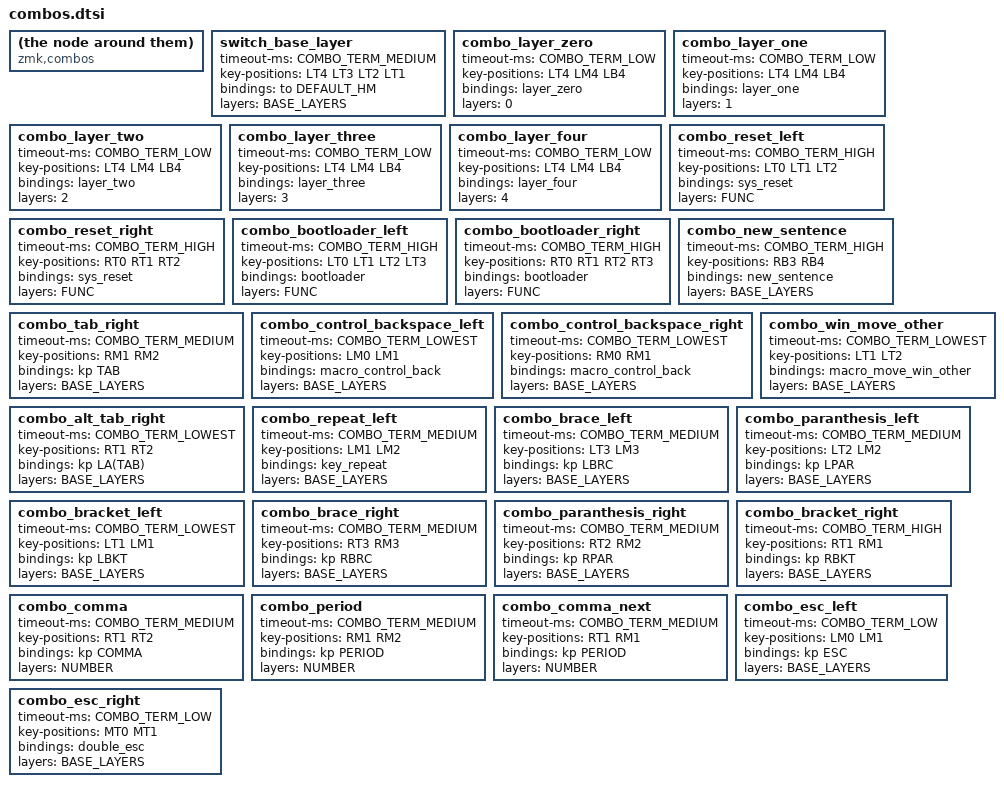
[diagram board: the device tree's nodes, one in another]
compatible = "zmk,combos";
#include "../zmk-nodefree-config/keypos_def/keypos_34keys.h"
#define KEYS_L LT0 LT1 LT2 LT3 LT4 LM0 LM1 LM2 LM3 LM4 LB0 LB1 LB2 LB3 LB4  // left-hand keys
#define KEYS_R RT0 RT1 RT2 RT3 RT4 RM0 RM1 RM2 RM3 RM4 RB0 RB1 RB2 RB3 RB4  // right-hand keys
#define THUMBS LH1 LH0 RH0 RH1  // tHumb keys

#define COMBO_TERM_LOWEST 15
#define COMBO_TERM_LOW 30
#define COMBO_TERM_MEDIUM 40
#define COMBO_TERM_HIGH 50

#define BASE_LAYERS DEFAULT_HM DEFAULT_HM_ONE DEFAULT_HM_TWO DEFAULT_HM_THREE DEFAULT_HM_NONE
// #undef COMBO_HOOK
// #define COMBO_HOOK global-quick-tap-ms = <100>;

/* 5 columns 
0	1	2	3	4		5	6	7	8	9
10	11	12	13	14		15	16	17	18	19
20	21	22	23	24		25	26	27	28	29
		30	31				32	33		
*/

/*                KEY POSITIONS

  ╭─────────────────────╮ ╭─────────────────────╮
  │ LT4 LT3 LT2 LT1 LT0 │ │ RT0 RT1 RT2 RT3 RT4 │
  │ LM4 LM3 LM2 LM1 LM0 │ │ RM0 RM1 RM2 RM3 RM4 │
  │ LB4 LB3 LB2 LB1 LB0 │ │ RB0 RB1 RB2 RB3 RB4 │
  ╰───────╮ LH2 LH1 LH0 │ │ RH0 RH1 RH2 ╭───────╯
          ╰─────────────╯ ╰─────────────╯ */


// layers
// What layer am I on?
// Device settings
// Tricks
// modifiers
// symbols
// keys

// layers

switch_base_layer {
    timeout-ms = <COMBO_TERM_MEDIUM>;
    key-positions = <LT4 LT3 LT2 LT1>;
    bindings = <&to DEFAULT_HM>;
    layers = <BASE_LAYERS>;
};


// What layer am I on?
combo_layer_zero {
    timeout-ms = <COMBO_TERM_LOW>;
    key-positions = <LT4 LM4 LB4>;
    bindings = <&layer_zero>;
    layers = <0>;
};

combo_layer_one {
    timeout-ms = <COMBO_TERM_LOW>;
    key-positions = <LT4 LM4 LB4>;
    bindings = <&layer_one>;
    layers = <1>;
};

combo_layer_two {
    timeout-ms = <COMBO_TERM_LOW>;
    key-positions = <LT4 LM4 LB4>;
    bindings = <&layer_two>;
    layers = <2>;
};

combo_layer_three {
    timeout-ms = <COMBO_TERM_LOW>;
    key-positions = <LT4 LM4 LB4>;
    bindings = <&layer_three>;
    layers = <3>;
};

combo_layer_four {
    timeout-ms = <COMBO_TERM_LOW>;
    key-positions = <LT4 LM4 LB4>;
    bindings = <&layer_four>;
    layers = <4>;
};

// Device settings

combo_reset_left {
    timeout-ms = <COMBO_TERM_HIGH>;
    key-positions = <LT0 LT1 LT2>;
    bindings = <&sys_reset>;
    layers = <FUNC>;
};
    
combo_reset_right {
    timeout-ms = <COMBO_TERM_HIGH>; 
    key-positions = <RT0 RT1 RT2>;
    bindings = <&sys_reset>;
    layers = <FUNC>;
};
    
combo_bootloader_left {
    timeout-ms = <COMBO_TERM_HIGH>;
    key-positions = <LT0 LT1 LT2 LT3>;
    bindings = <&bootloader>;
    layers = <FUNC>;
};

combo_bootloader_right {
    timeout-ms = <COMBO_TERM_HIGH>;
    key-positions = <RT0 RT1 RT2 RT3>;
    bindings = <&bootloader>;
    layers = <FUNC>;
};


// Tricks 

combo_new_sentence {
    timeout-ms = <COMBO_TERM_HIGH>;
    key-positions = <RB3 RB4>;
    bindings = <&new_sentence>;
    layers = <BASE_LAYERS>;
};


// modifiers

combo_tab_right {
    timeout-ms = <COMBO_TERM_MEDIUM>;
    key-positions = <RM1 RM2>;
    bindings = <&kp TAB>;
    layers = <BASE_LAYERS>;
};

combo_control_backspace_left {
    timeout-ms = <COMBO_TERM_LOWEST>;
    key-positions = <LM0 LM1>;
    bindings = <&macro_control_back>;
    layers = <BASE_LAYERS>;
};

combo_control_backspace_right {
    timeout-ms = <COMBO_TERM_LOWEST>;
    key-positions = <RM0 RM1>;
    bindings = <&macro_control_back>;
    layers = <BASE_LAYERS>;
};

combo_win_move_other {
    timeout-ms = <COMBO_TERM_LOWEST>; // tried 30 ms, was still getting false positives
    key-positions = <LT1 LT2>;
    bindings = <&macro_move_win_other>;
    layers = <BASE_LAYERS>;
};

combo_alt_tab_right {
    timeout-ms = <COMBO_TERM_LOWEST>; // tried low, but want to see if the lowest willl reduce all fase positives without sacrifiicing abiltity
    key-positions = <RT1 RT2>;
    bindings = <&kp LA(TAB)>;
    layers = <BASE_LAYERS>;
};

combo_repeat_left {
    timeout-ms = <COMBO_TERM_MEDIUM>;
    key-positions = <LM1 LM2>;   
    bindings = <&key_repeat>;
    layers = <BASE_LAYERS>;
};

// symbols
combo_brace_left {
    timeout-ms = <COMBO_TERM_MEDIUM>;
    key-positions = <LT3 LM3>;
    bindings = <&kp LBRC>;
    layers = <BASE_LAYERS>;
};

combo_paranthesis_left {
    timeout-ms = <COMBO_TERM_MEDIUM>;
    key-positions = <LT2 LM2>;
    bindings = <&kp LPAR>;
    layers = <BASE_LAYERS>;
};

combo_bracket_left {
    timeout-ms = <COMBO_TERM_LOWEST>;
    key-positions = <LT1 LM1>;
    bindings = <&kp LBKT>;
    layers = <BASE_LAYERS>;
};

combo_brace_right {
    timeout-ms = <COMBO_TERM_MEDIUM>;
    key-positions = <RT3 RM3>;
    bindings = <&kp RBRC>;
    layers = <BASE_LAYERS>;
};

combo_paranthesis_right {
    timeout-ms = <COMBO_TERM_MEDIUM>;
    key-positions = <RT2 RM2>;
    bindings = <&kp RPAR>;
    layers = <BASE_LAYERS>;
};

combo_bracket_right {
    timeout-ms = <COMBO_TERM_HIGH>;
    key-positions = <RT1 RM1>;
    bindings = <&kp RBKT>;
    layers = <BASE_LAYERS>;
};

combo_comma {
    timeout-ms = <COMBO_TERM_MEDIUM>;
    key-positions = <RT1 RT2>;
    bindings = <&kp COMMA>;
    layers = <NUMBER>;
};

combo_period {
    timeout-ms = <COMBO_TERM_MEDIUM>;
    key-positions = <RM1 RM2>;
    bindings = <&kp PERIOD>;
    layers = <NUMBER>;
};

combo_comma_next {
    timeout-ms = <COMBO_TERM_MEDIUM>;
    key-positions = <RT1 RM1>;
    bindings = <&kp PERIOD>;
    layers = <NUMBER>;
};


// modifiers 2 -- not sure if this placement is what was fixing my collisions with brackets
combo_esc_left {
    timeout-ms = <COMBO_TERM_LOW>;
    key-positions = <LM0 LM1>;
    bindings = <&kp ESC>;
    layers = <BASE_LAYERS>;
};

combo_esc_right {
    timeout-ms = <COMBO_TERM_LOW>;
    key-positions = <MT0 MT1>;
    bindings = <&double_esc>;
    layers = <BASE_LAYERS>;
};
